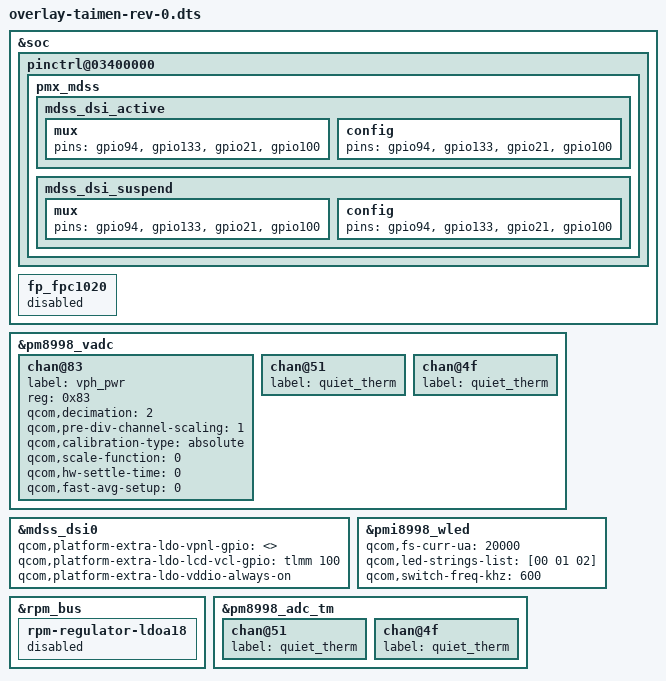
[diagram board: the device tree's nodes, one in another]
/* Copyright (c) 2017, The Linux Foundation. All rights reserved.
 *
 * This program is free software; you can redistribute it and/or modify
 * it under the terms of the GNU General Public License version 2 and
 * only version 2 as published by the Free Software Foundation.
 *
 * This program is distributed in the hope that it will be useful,
 * but WITHOUT ANY WARRANTY; without even the implied warranty of
 * MERCHANTABILITY or FITNESS FOR A PARTICULAR PURPOSE.  See the
 * GNU General Public License for more details.
 */

/dts-v1/;
/plugin/;

#include "msm8998-taimen.dtsi"

&soc {
	pinctrl@03400000 {
		pmx_mdss {
			mdss_dsi_active {
				mux {
					pins = "gpio94", "gpio133", "gpio21", "gpio100";
				};
				config {
					pins = "gpio94", "gpio133", "gpio21", "gpio100";
				};
			};
			mdss_dsi_suspend {
				mux {
					pins = "gpio94", "gpio133", "gpio21", "gpio100";
				};
				config {
					pins = "gpio94", "gpio133", "gpio21", "gpio100";
				};
			};
		};
	};
};

&pm8998_vadc {
	chan@83 {
		label = "vph_pwr";
		reg = <0x83>;
		qcom,decimation = <2>;
		qcom,pre-div-channel-scaling = <1>;
		qcom,calibration-type = "absolute";
		qcom,scale-function = <0>;
		qcom,hw-settle-time = <0>;
		qcom,fast-avg-setup = <0>;
	};
};

&mdss_dsi0 {
	/* LCD only */
	qcom,platform-extra-ldo-vpnl-gpio = <>;
	qcom,platform-extra-ldo-lcd-vcl-gpio = <&tlmm 100 0>;
	qcom,platform-extra-ldo-vddio-always-on;
};

&pmi8998_wled {
	status = "okay";
	qcom,fs-curr-ua = <20000>;
	qcom,led-strings-list = [00 01 02];
	/* qcom,en-cabc; */
	qcom,switch-freq-khz = <600>;
};

&soc {
	fp_fpc1020 {
		status = "disabled";
	};
};

&rpm_bus {
	rpm-regulator-ldoa18 {
		status = "disabled";
	};
};

&pm8998_vadc {
	chan@51 {
		label = "quiet_therm";
	};
	chan@4f {
		label = "quiet_therm";
	};
};

&pm8998_adc_tm {
	chan@51 {
		label = "quiet_therm";
	};
	chan@4f {
		label = "quiet_therm";
	};
};
